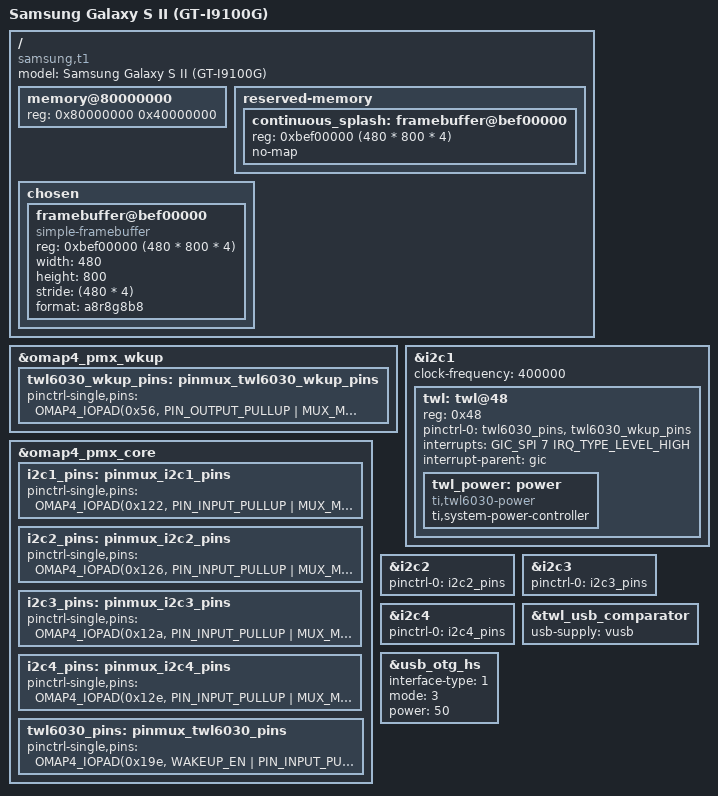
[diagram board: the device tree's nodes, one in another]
// SPDX-License-Identifier: (GPL-2.0 OR MIT)
/dts-v1/;
#include "dt-bindings/gpio/gpio.h"
#include <dt-bindings/interrupt-controller/irq.h>
#include <dt-bindings/input/input.h>
#include "omap443x.dtsi"

/ {
	model = "Samsung Galaxy S II (GT-I9100G)";
	compatible = "samsung,t1", "ti,omap4430", "ti,omap4";

	memory@80000000 {
		device_type = "memory";
		reg = <0x80000000 0x40000000>; /* 1 GB */
	};

	reserved-memory {
		#address-cells = <1>;
		#size-cells = <1>;
		ranges;


		continuous_splash: framebuffer@bef00000{
			//The framebuffer address is specific to your device
			reg = <0xbef00000 (480 * 800 * 4)>;
			no-map;
		};
	};

	chosen {
		#address-cells = <1>;
		#size-cells = <1>;
		ranges;

		framebuffer@bef00000 {
			compatible = "simple-framebuffer";
			reg = <0xbef00000 (480 * 800 * 4)>;
			width = <480>;
			height = <800>;
			stride = <(480 * 4)>;
			format = "a8r8g8b8";
		};
	};
};

&omap4_pmx_wkup {
	twl6030_wkup_pins: pinmux_twl6030_wkup_pins {
		pinctrl-single,pins = <
			OMAP4_IOPAD(0x56, PIN_OUTPUT_PULLUP | MUX_MODE2)	/* fref_clk3_req.sys_drm_msecure */
		>;
	};
};

&omap4_pmx_core {
	i2c1_pins: pinmux_i2c1_pins {
		pinctrl-single,pins = <
			OMAP4_IOPAD(0x122, PIN_INPUT_PULLUP | MUX_MODE0)	/* i2c1_scl */
			OMAP4_IOPAD(0x124, PIN_INPUT_PULLUP | MUX_MODE0)	/* i2c1_sda */
		>;
	};

	i2c2_pins: pinmux_i2c2_pins {
		pinctrl-single,pins = <
			OMAP4_IOPAD(0x126, PIN_INPUT_PULLUP | MUX_MODE0)	/* i2c2_scl */
			OMAP4_IOPAD(0x128, PIN_INPUT_PULLUP | MUX_MODE0)	/* i2c2_sda */
		>;
	};

	i2c3_pins: pinmux_i2c3_pins {
		pinctrl-single,pins = <
			OMAP4_IOPAD(0x12a, PIN_INPUT_PULLUP | MUX_MODE0)	/* i2c3_scl */
			OMAP4_IOPAD(0x12c, PIN_INPUT_PULLUP | MUX_MODE0)	/* i2c3_sda */
		>;
	};

	i2c4_pins: pinmux_i2c4_pins {
		pinctrl-single,pins = <
			OMAP4_IOPAD(0x12e, PIN_INPUT_PULLUP | MUX_MODE0)	/* i2c4_scl */
			OMAP4_IOPAD(0x130, PIN_INPUT_PULLUP | MUX_MODE0)	/* i2c4_sda */
		>;
	};

	twl6030_pins: pinmux_twl6030_pins {
		pinctrl-single,pins = <
			OMAP4_IOPAD(0x19e, WAKEUP_EN | PIN_INPUT_PULLUP | MUX_MODE0)	/* sys_nirq1.sys_nirq1 */
		>;
	};
};

&i2c1 {
	// We need i2c1 muxed early on the boot process for pmic
	// bootloader already done it for us
	// pinctrl-names = "default";
	// pinctrl-0 = <&i2c1_pins>;

	clock-frequency = <400000>;

	twl: twl@48 {
		reg = <0x48>;

		pinctrl-names = "default";
		pinctrl-0 = <
			&twl6030_pins
			&twl6030_wkup_pins
		>;

		/* SPI = 0, IRQ# = 7, 4 = active high level-sensitive */
		interrupts = <GIC_SPI 7 IRQ_TYPE_LEVEL_HIGH>; /* IRQ_SYS_1N cascaded to gic */
		interrupt-parent = <&gic>;

		twl_power: power {
			compatible = "ti,twl6030-power";
			ti,system-power-controller;
		};
	};
};

&i2c2 {
	pinctrl-names = "default";
	pinctrl-0 = <&i2c2_pins>;
};

&i2c3 {
	pinctrl-names = "default";
	pinctrl-0 = <&i2c3_pins>;
};

&i2c4 {
	pinctrl-names = "default";
	pinctrl-0 = <&i2c4_pins>;
};

#include "twl6030.dtsi"

&twl_usb_comparator {
	usb-supply = <&vusb>;
};

&usb_otg_hs {
	interface-type = <1>;
	mode = <3>;
	power = <50>;
};
